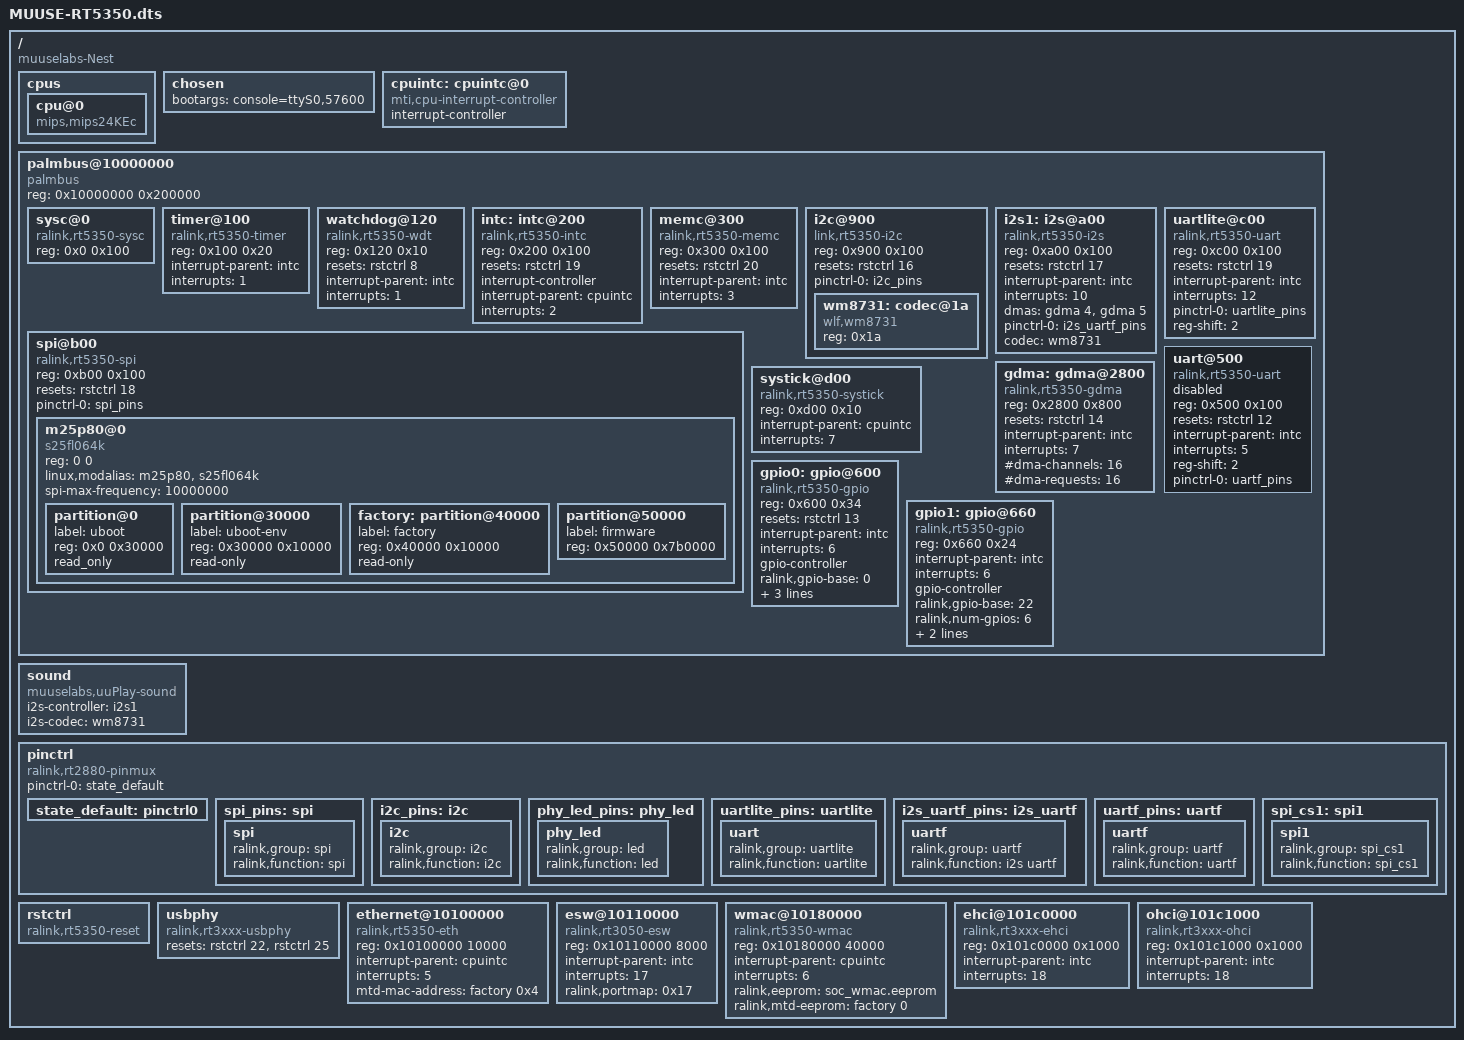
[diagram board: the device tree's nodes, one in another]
/dts-v1/;

/ {
	compatible = "muuselabs-Nest", "ralink,rt5350-soc";
	#address-cells = <1>;
	#size-cells = <1>;

	cpus {
		cpu@0 {
			compatible = "mips,mips24KEc";
		};
	};

	chosen {
		bootargs = "console=ttyS0,57600";
	};

	cpuintc: cpuintc@0 {
		#address-cells = <0>;
		#interrupt-cells = <1>;
		interrupt-controller;
		compatible = "mti,cpu-interrupt-controller";
	};

	palmbus@10000000 {
		compatible = "palmbus";
		reg = <0x10000000 0x200000>;
		ranges = <0x0 0x10000000 0x1FFFFF>;

		#address-cells = <1>;
		#size-cells = <1>;

		/* System Control p22 */
		/* use to configure SYSCFG and GPIOMODE registers to specify pin functions */
		sysc@0 {
			compatible = "ralink,rt5350-sysc", "ralink,rt3050-sysc";
			reg = <0x0 0x100>;
		};

		/* Timer p31 */
		timer@100 {
			compatible = "ralink,rt5350-timer", "ralink,rt2880-timer";
			reg = <0x100 0x20>;

			interrupt-parent = <&intc>;
			interrupts = <1>;
		};

		/* Watchdog, part of timer? */
		watchdog@120 {
			compatible = "ralink,rt5350-wdt", "ralink,rt2880-wdt";
			reg = <0x120 0x10>;

			resets = <&rstctrl 8>;
			reset-names = "wdt";

			interrupt-parent = <&intc>;
			interrupts = <1>;
		};

		/* Interrupt controller p37 */
		intc: intc@200 {
			compatible = "ralink,rt5350-intc", "ralink,rt2880-intc";
			reg = <0x200 0x100>;

			resets = <&rstctrl 19>;
			reset-names = "intc";

			interrupt-controller;
			#interrupt-cells = <1>;

			interrupt-parent = <&cpuintc>;
			interrupts = <2>;
		};
		
		/* Memory Controller p92 */
		memc@300 {
			compatible = "ralink,rt5350-memc", "ralink,rt3050-memc";
			reg = <0x300 0x100>;

			resets = <&rstctrl 20>;
			reset-names = "mc";

			interrupt-parent = <&intc>;
			interrupts = <3>;
		};

		/* I2C controller p62 */
		i2c@900 {
			compatible = "link,rt5350-i2c", "ralink,rt2880-i2c";
			reg = <0x900 0x100>;

			resets = <&rstctrl 16>;
			reset-names = "i2c";

			#address-cells = <1>;
			#size-cells = <0>;

			pinctrl-names = "default";
			pinctrl-0 = <&i2c_pins>;

			
			wm8731: codec@1a {
				compatible = "wlf,wm8731";
				reg = <0x1a>;
			};	
		};
		
		/* I2S Controller p82 */
		i2s1: i2s@a00 {
			/* compatible = "ralink,rt5350-i2s", "ralink,mt7620-i2s"; */
			compatible = "ralink,rt5350-i2s";
			reg = <0xa00 0x100>;

			resets = <&rstctrl 17>;
			reset-names = "i2s";

			interrupt-parent = <&intc>;
			interrupts = <10>;

			dmas = <&gdma 4>,
				<&gdma 5>;
			dma-names = "tx", "rx";
			
			pinctrl-names = "default";
			pinctrl-0 = <&i2s_uartf_pins>;	
			
			codec = <&wm8731>;
		};		

		/* SPI Controller p78 */
		spi@b00 {
			compatible = "ralink,rt5350-spi", "ralink,rt2880-spi";
			reg = <0xb00 0x100>;

			resets = <&rstctrl 18>;
			reset-names = "spi";

			#address-cells = <1>;
			#size-cells = <1>;

			pinctrl-names = "default";
			pinctrl-0 = <&spi_pins>;

			/* Patch proposal from Vonger for SD card debugging
			spidev@1 {
    				compatible = "linux,spidev";
    				reg = <1>;
    				spi-max-frequency = <1000000>;
				};
			*/

			m25p80@0 {
				#address-cells = <1>;
				#size-cells = <1>;
				compatible = "s25fl064k";
				reg = <0 0>;
				linux,modalias = "m25p80", "s25fl064k";
				spi-max-frequency = <10000000>;

				partition@0 {
					label = "uboot";
					reg = <0x0 0x30000>;
					read_only;
				};

				partition@30000 {
					label = "uboot-env";
					reg = <0x30000 0x10000>;
					read-only;
				};

				factory: partition@40000 {
					label = "factory";
					reg = <0x40000 0x10000>;
					read-only;
				};

				partition@50000 {
					label = "firmware";
					reg = <0x50000 0x7b0000>;
				};
			};



		};

		/* UART lite p50 */
		uartlite@c00 {
			compatible = "ralink,rt5350-uart", "ralink,rt2880-uart", "ns16550a";
			reg = <0xc00 0x100>;

			resets = <&rstctrl 19>;
			reset-names = "uartl";

			interrupt-parent = <&intc>;
			interrupts = <12>;

			pinctrl-names = "default";
			pinctrl-0 = <&uartlite_pins>;

			reg-shift = <2>;
		};
		
		/* UART Full p43 */
		/* Moved here to appear as ttyS1 and not override the UART lite from being ttyS0 */
		uart@500 {
			compatible = "ralink,rt5350-uart", "ralink,rt2880-uart", "ns16550a";
			reg = <0x500 0x100>;

			resets = <&rstctrl 12>;
			reset-names = "uart";

			interrupt-parent = <&intc>;
			interrupts = <5>;

			reg-shift = <2>;
			
			pinctrl-names = "default";
			pinctrl-0 = <&uartf_pins>;
			
			status = "enabled";			
		};		
		
		/* System Tick counter p42 */
		systick@d00 {
			compatible = "ralink,rt5350-systick", "ralink,cevt-systick";
			reg = <0xd00 0x10>;

			interrupt-parent = <&cpuintc>;
			interrupts = <7>;
		};
		
		/* TODO: Add PCM Controller @2000 p66 */
		
		/* Generic DMA Controller p77 */
		gdma: gdma@2800 {
			compatible = "ralink,rt5350-gdma", "ralink,rt2880-gdma";
			reg = <0x2800 0x800>;

			resets = <&rstctrl 14>;
			reset-names = "dma";

			interrupt-parent = <&intc>;
			interrupts = <7>;

			#dma-cells = <1>;
			#dma-channels = <16>;
			#dma-requests = <16>;
		};	
		
		
		/* Programmable I/O p56 */
		/* GPIO(21:0) */
		/* Groups:
		           JTAG		GPIO(21:17)
			   UARTL	GPIO(16:15)
			   UARTF	GPIO(14:7)
			   SPI		GPIO(6:3)
			   I2C		GPIO(2:1)
			   GPIO		GPIO0	
			   
		*/
		gpio0: gpio@600 {
			compatible = "ralink,rt5350-gpio", "ralink,rt2880-gpio";
			reg = <0x600 0x34>;

			resets = <&rstctrl 13>;
			reset-names = "pio";

			interrupt-parent = <&intc>;
			interrupts = <6>;

			gpio-controller;
			#gpio-cells = <2>;

			ralink,gpio-base = <0>;
			ralink,num-gpios = <22>;
			ralink,register-map = [ 00 04 08 0c
						20 24 28 2c
						30 34 ];
		};

		/* GPIO(27:22) */
		/* Groups:
			SPI_CS1		GPIO27
			SW_PHY_LED	GPIO(26:22)
			   
		*/
		gpio1: gpio@660 {
			compatible = "ralink,rt5350-gpio", "ralink,rt2880-gpio";
			reg = <0x660 0x24>;

			interrupt-parent = <&intc>;
			interrupts = <6>;

			gpio-controller;
			#gpio-cells = <2>;

			ralink,gpio-base = <22>;
			ralink,num-gpios = <6>;
			ralink,register-map = [ 00 04 08 0c
						10 14 18 1c
						20 24 ];

		};	
	};
	
	sound {
		compatible = "muuselabs,uuPlay-sound";
		i2s-controller = <&i2s1>;
		i2s-codec = <&wm8731>;
	};	

	pinctrl {
		compatible = "ralink,rt2880-pinmux";

		pinctrl-names = "default";
		pinctrl-0 = <&state_default>;

		state_default: pinctrl0 {
			/*
			gpio {
				ralink,group = "jtag", "led", "spi_cs1";
				ralink,function = "gpio";
			};
			*/		
		
		};
		spi_pins: spi {
			spi {
				ralink,group = "spi";
				ralink,function = "spi";
			};
		};
		i2c_pins: i2c {
			i2c {
				ralink,group = "i2c";
				ralink,function = "i2c";
			};
		};
		phy_led_pins: phy_led {
			phy_led {
				ralink,group = "led";
				ralink,function = "led";
			};
		};
		uartlite_pins: uartlite {
			uart {
				ralink,group = "uartlite";
				ralink,function = "uartlite";
			};
		};

		
		/* Theo adding i2s & uartf pins */
		i2s_uartf_pins: i2s_uartf {
			uartf {
				ralink,group = "uartf";
				ralink,function = "i2s uartf";
			};
		};		
		
		uartf_pins: uartf {
			uartf {
				ralink,group = "uartf";
				ralink,function = "uartf";
			};
		};		
		
		spi_cs1: spi1 {
			spi1 {
				ralink,group = "spi_cs1";
				ralink,function = "spi_cs1";
			};
		};
	};

	rstctrl: rstctrl {
		compatible = "ralink,rt5350-reset", "ralink,rt2880-reset";
		#reset-cells = <1>;
	};

	usbphy {
		compatible = "ralink,rt3xxx-usbphy";

		resets = <&rstctrl 22 &rstctrl 25>;
		reset-names = "host", "device";
	};

	ethernet@10100000 {
		compatible = "ralink,rt5350-eth";
		reg = <0x10100000 10000>;

		interrupt-parent = <&cpuintc>;
		interrupts = <5>;
		
		mtd-mac-address = <&factory 0x4>;
	};

	esw@10110000 {
		compatible = "ralink,rt3050-esw";
		reg = <0x10110000 8000>;

		interrupt-parent = <&intc>;
		interrupts = <17>;
		
		ralink,portmap = <0x17>;		
		
	};

	wmac@10180000 {
		compatible = "ralink,rt5350-wmac", "ralink,rt2880-wmac";
		reg = <0x10180000 40000>;

		interrupt-parent = <&cpuintc>;
		interrupts = <6>;

		ralink,eeprom = "soc_wmac.eeprom";
		
		ralink,mtd-eeprom = <&factory 0>;		
	};

	ehci@101c0000 {
		compatible = "ralink,rt3xxx-ehci", "ehci-platform";
		reg = <0x101c0000 0x1000>;

		interrupt-parent = <&intc>;
		interrupts = <18>;
	};

	ohci@101c1000 {
		compatible = "ralink,rt3xxx-ohci", "ohci-platform";
		reg = <0x101c1000 0x1000>;

		interrupt-parent = <&intc>;
		interrupts = <18>;
	};	
	

};
